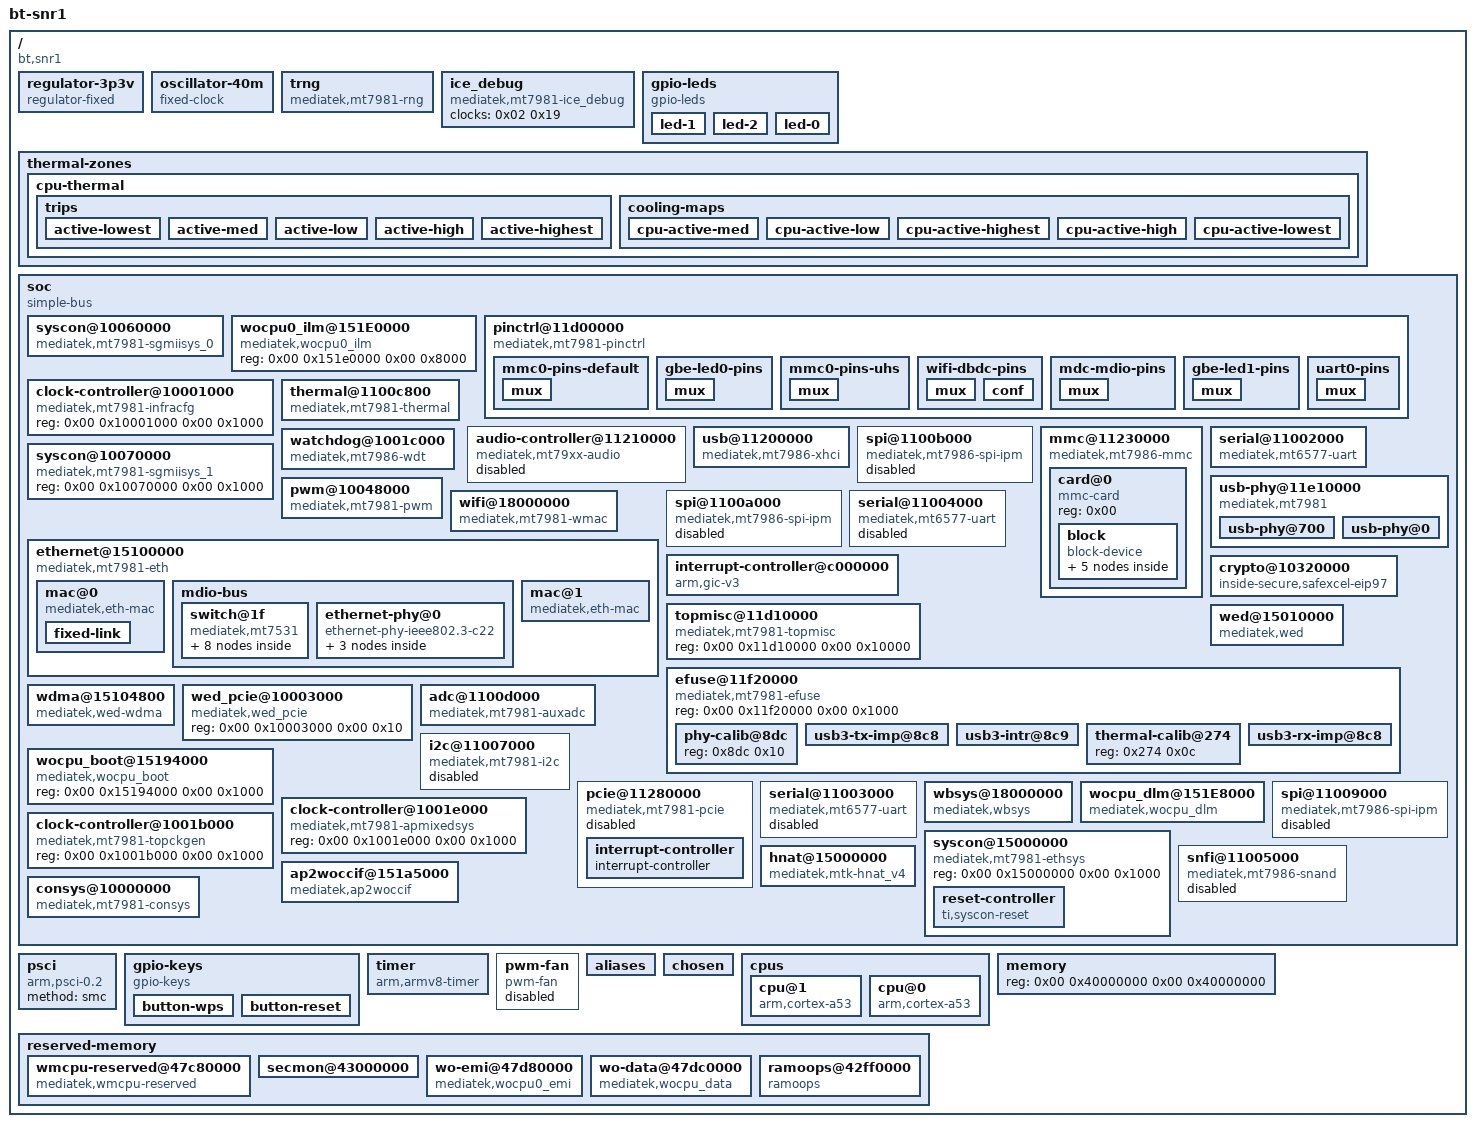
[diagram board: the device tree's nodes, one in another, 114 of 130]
/dts-v1/;

/ {
	#address-cells = <0x02>;
	model = "bt-snr1";
	#size-cells = <0x02>;
	interrupt-parent = <0x01>;
	compatible = "bt,snr1", "mediatek,mt7981";

	regulator-3p3v {
		regulator-max-microvolt = <0x325aa0>;
		regulator-boot-on;
		regulator-always-on;
		regulator-min-microvolt = <0x325aa0>;
		regulator-name = "fixed-3.3V";
		compatible = "regulator-fixed";
		phandle = <0x0c>;
	};

	oscillator-40m {
		clock-output-names = "clkxtal";
		#clock-cells = <0x00>;
		clock-frequency = <0x2625a00>;
		compatible = "fixed-clock";
		phandle = <0x22>;
	};

	trng {
		compatible = "mediatek,mt7981-rng";
	};

	ice_debug {
		clock-names = "ice_dbg";
		clocks = <0x02 0x19>;
		compatible = "mediatek,mt7981-ice_debug", "mediatek,mt2701-ice_debug";
		phandle = <0x21>;
	};

	gpio-leds {
		compatible = "gpio-leds";

		led-1 {
			label = "green:status";
			phandle = <0x52>;
			gpios = <0x10 0x0b 0x00>;
		};

		led-2 {
			label = "yellow:status";
			phandle = <0x53>;
			gpios = <0x10 0x0c 0x00>;
		};

		led-0 {
			label = "red:status";
			phandle = <0x51>;
			gpios = <0x10 0x0d 0x00>;
		};
	};

	thermal-zones {

		cpu-thermal {
			polling-delay = <0x3e8>;
			polling-delay-passive = <0x3e8>;
			thermal-sensors = <0x1a 0x00>;
			phandle = <0x4f>;

			trips {

				active-lowest {
					temperature = <0x9c40>;
					hysteresis = <0x7d0>;
					type = "active";
					phandle = <0x20>;
				};

				active-med {
					temperature = <0xc350>;
					hysteresis = <0x7d0>;
					type = "active";
					phandle = <0x1e>;
				};

				active-low {
					temperature = <0xafc8>;
					hysteresis = <0x7d0>;
					type = "active";
					phandle = <0x1f>;
				};

				active-high {
					temperature = <0xea60>;
					hysteresis = <0x7d0>;
					type = "active";
					phandle = <0x1d>;
				};

				active-highest {
					temperature = <0x11170>;
					hysteresis = <0x7d0>;
					type = "active";
					phandle = <0x1c>;
				};
			};

			cooling-maps {

				cpu-active-med {
					trip = <0x1e>;
					cooling-device = <0x1b 0x03 0x03>;
				};

				cpu-active-low {
					trip = <0x1f>;
					cooling-device = <0x1b 0x02 0x02>;
				};

				cpu-active-highest {
					trip = <0x1c>;
					cooling-device = <0x1b 0x07 0x07>;
				};

				cpu-active-high {
					trip = <0x1d>;
					cooling-device = <0x1b 0x05 0x05>;
				};

				cpu-active-lowest {
					trip = <0x20>;
					cooling-device = <0x1b 0x01 0x01>;
				};
			};
		};
	};

	soc {
		#address-cells = <0x02>;
		#size-cells = <0x02>;
		compatible = "simple-bus";
		ranges;

		syscon@10060000 {
			mediatek,pnswap;
			#clock-cells = <0x01>;
			compatible = "mediatek,mt7981-sgmiisys_0", "syscon";
			reg = <0x00 0x10060000 0x00 0x1000>;
			phandle = <0x12>;
		};

		wocpu0_ilm@151E0000 {
			compatible = "mediatek,wocpu0_ilm";
			reg = <0x00 0x151e0000 0x00 0x8000>;
			phandle = <0x4a>;
		};

		pinctrl@11d00000 {
			reg-names = "gpio", "iocfg_rt", "iocfg_rm", "iocfg_rb", "iocfg_lb", "iocfg_bl", "iocfg_tm", "iocfg_tl", "eint";
			gpio-controller;
			interrupts = <0x00 0xe1 0x04>;
			interrupt-parent = <0x01>;
			compatible = "mediatek,mt7981-pinctrl";
			#interrupt-cells = <0x02>;
			reg = <0x00 0x11d00000 0x00 0x1000 0x00 0x11c00000 0x00 0x1000 0x00 0x11c10000 0x00 0x1000 0x00 0x11d20000 0x00 0x1000 0x00 0x11e00000 0x00 0x1000 0x00 0x11e20000 0x00 0x1000 0x00 0x11f00000 0x00 0x1000 0x00 0x11f10000 0x00 0x1000 0x00 0x1000b000 0x00 0x1000>;
			phandle = <0x10>;
			#gpio-cells = <0x02>;
			gpio-ranges = <0x10 0x00 0x00 0x38>;
			interrupt-controller;

			mmc0-pins-default {
				phandle = <0x0d>;

				mux {
					function = "flash";
					groups = "emmc_45";
				};
			};

			gbe-led0-pins {
				phandle = <0x3b>;

				mux {
					function = "led";
					groups = "gbe_led0";
				};
			};

			mmc0-pins-uhs {
				phandle = <0x0e>;

				mux {
					function = "flash";
					groups = "emmc_45";
				};
			};

			wifi-dbdc-pins {
				phandle = <0x3a>;

				mux {
					function = "eth";
					groups = "wf0_mode1";
				};

				conf {
					pins = "WF_HB1", "WF_HB2", "WF_HB3", "WF_HB4", "WF_HB0", "WF_HB0_B", "WF_HB5", "WF_HB6", "WF_HB7", "WF_HB8", "WF_HB9", "WF_HB10", "WF_TOP_CLK", "WF_TOP_DATA", "WF_XO_REQ", "WF_CBA_RESETB", "WF_DIG_RESETB";
					drive-strength = <0x04>;
				};
			};

			mdc-mdio-pins {
				phandle = <0x39>;

				mux {
					function = "eth";
					groups = "smi_mdc_mdio";
				};
			};

			gbe-led1-pins {
				phandle = <0x3c>;

				mux {
					function = "led";
					groups = "gbe_led1";
				};
			};

			uart0-pins {
				phandle = <0x06>;

				mux {
					function = "uart";
					groups = "uart0";
				};
			};
		};

		clock-controller@10001000 {
			#clock-cells = <0x01>;
			compatible = "mediatek,mt7981-infracfg", "syscon";
			reg = <0x00 0x10001000 0x00 0x1000>;
			phandle = <0x02>;
		};

		thermal@1100c800 {
			nvmem-cells = <0x07>;
			clock-names = "therm", "auxadc";
			interrupts = <0x00 0x8a 0x04>;
			clocks = <0x02 0x1d 0x02 0x30>;
			mediatek,apmixedsys = <0x09>;
			#thermal-sensor-cells = <0x01>;
			compatible = "mediatek,mt7981-thermal", "mediatek,mt7986-thermal";
			nvmem-cell-names = "calibration-data";
			reg = <0x00 0x1100c800 0x00 0x800>;
			phandle = <0x1a>;
			mediatek,auxadc = <0x08>;
		};

		audio-controller@11210000 {
			clock-names = "aud_bus_ck", "aud_26m_ck", "aud_l_ck", "aud_aud_ck", "aud_eg2_ck", "aud_sel";
			assigned-clocks = <0x03 0x65 0x03 0x66 0x03 0x67 0x03 0x68>;
			assigned-clock-parents = <0x03 0x10 0x03 0x12 0x03 0x10 0x03 0x12>;
			interrupts = <0x00 0x6a 0x04>;
			clocks = <0x02 0x13 0x02 0x14 0x02 0x15 0x02 0x16 0x02 0x17 0x03 0x65>;
			compatible = "mediatek,mt79xx-audio";
			status = "disabled";
			reg = <0x00 0x11210000 0x00 0x9000>;
			phandle = <0x35>;
		};

		usb@11200000 {
			clock-names = "sys_ck", "ref_ck", "mcu_ck", "dma_ck", "xhci_ck";
			reg-names = "mac", "ippc";
			vusb33-supply = <0x0c>;
			interrupts = <0x00 0xad 0x04>;
			clocks = <0x02 0x37 0x02 0x38 0x02 0x35 0x02 0x36 0x03 0x6b>;
			compatible = "mediatek,mt7986-xhci", "mediatek,mtk-xhci";
			status = "okay";
			phys = <0x0a 0x03 0x0b 0x04>;
			reg = <0x00 0x11200000 0x00 0x2e00 0x00 0x11203e00 0x00 0x100>;
			phandle = <0x34>;
		};

		spi@1100b000 {
			#address-cells = <0x01>;
			clock-names = "parent-clk", "sel-clk", "spi-clk", "hclk";
			interrupts = <0x00 0x8d 0x04>;
			clocks = <0x03 0x02 0x03 0x4f 0x02 0x28 0x02 0x2a>;
			#size-cells = <0x00>;
			compatible = "mediatek,mt7986-spi-ipm", "mediatek,spi-ipm";
			status = "disabled";
			reg = <0x00 0x1100b000 0x00 0x100>;
			phandle = <0x33>;
		};

		mmc@11230000 {
			pinctrl-names = "default", "state_uhs";
			pinctrl-0 = <0x0d>;
			clock-names = "source", "hclk", "axi_cg", "ahb_cg";
			assigned-clocks = <0x03 0x54 0x03 0x55>;
			assigned-clock-parents = <0x03 0x02 0x03 0x1c>;
			bus-width = <0x08>;
			non-removable;
			interrupts = <0x00 0x8f 0x04>;
			clocks = <0x02 0x2c 0x02 0x2d 0x02 0x2f 0x02 0x2e>;
			vmmc-supply = <0x0c>;
			compatible = "mediatek,mt7986-mmc", "mediatek,mt7981-mmc";
			pinctrl-1 = <0x0e>;
			status = "okay";
			reg = <0x00 0x11230000 0x00 0x1000 0x00 0x11c20000 0x00 0x1000>;
			phandle = <0x36>;
			max-frequency = <0x5f5e100>;
			cap-mmc-highspeed;

			card@0 {
				compatible = "mmc-card";
				reg = <0x00>;

				block {
					compatible = "block-device";

					partitions {

						block-partition-factory {
							partname = "factory";

							nvmem-layout {
								#address-cells = <0x01>;
								#size-cells = <0x01>;
								compatible = "fixed-layout";

								eeprom@0 {
									reg = <0x00 0x1000>;
									phandle = <0x37>;
								};

								macaddr@2a {
									#nvmem-cell-cells = <0x01>;
									compatible = "mac-base";
									reg = <0x2a 0x06>;
									phandle = <0x17>;
								};
							};
						};
					};
				};
			};
		};

		serial@11002000 {
			pinctrl-names = "default";
			pinctrl-0 = <0x06>;
			clock-names = "baud", "bus";
			assigned-clocks = <0x03 0x50 0x02 0x01>;
			assigned-clock-parents = <0x03 0x00 0x03 0x50>;
			interrupts = <0x00 0x7b 0x04>;
			clocks = <0x02 0x01 0x02 0x1f>;
			compatible = "mediatek,mt6577-uart";
			status = "okay";
			reg = <0x00 0x11002000 0x00 0x400>;
			phandle = <0x2c>;
		};

		syscon@10070000 {
			#clock-cells = <0x01>;
			compatible = "mediatek,mt7981-sgmiisys_1", "syscon";
			reg = <0x00 0x10070000 0x00 0x1000>;
			phandle = <0x13>;
		};

		usb-phy@11e10000 {
			#address-cells = <0x01>;
			#size-cells = <0x01>;
			compatible = "mediatek,mt7981", "mediatek,generic-tphy-v2";
			ranges = <0x00 0x00 0x11e10000 0x1700>;
			status = "okay";
			phandle = <0x3d>;

			usb-phy@700 {
				clock-names = "ref";
				clocks = <0x03 0x64>;
				#phy-cells = <0x01>;
				status = "okay";
				reg = <0x700 0x900>;
				mediatek,syscon-type = <0x11 0x218 0x00>;
				phandle = <0x0b>;
			};

			usb-phy@0 {
				clock-names = "ref";
				clocks = <0x03 0x6c>;
				#phy-cells = <0x01>;
				reg = <0x00 0x700>;
				phandle = <0x0a>;
			};
		};

		watchdog@1001c000 {
			#reset-cells = <0x01>;
			interrupts = <0x00 0x6e 0x04>;
			compatible = "mediatek,mt7986-wdt", "mediatek,mt6589-wdt";
			status = "okay";
			reg = <0x00 0x1001c000 0x00 0x1000>;
			phandle = <0x28>;
		};

		pwm@10048000 {
			clock-names = "top", "main", "pwm1", "pwm2", "pwm3";
			clocks = <0x02 0x0e 0x02 0x0d 0x02 0x0f 0x02 0x10 0x02 0x11>;
			#pwm-cells = <0x02>;
			compatible = "mediatek,mt7981-pwm";
			reg = <0x00 0x10048000 0x00 0x1000>;
			phandle = <0x29>;
		};

		wifi@18000000 {
			compatible = "mediatek,mt7981-wmac";
			phandle = <0x4d>;
		};

		ethernet@15100000 {
			#reset-cells = <0x01>;
			#address-cells = <0x01>;
			clock-names = "fe", "gp2", "gp1", "wocpu0", "sgmii_tx250m", "sgmii_rx250m", "sgmii_cdr_ref", "sgmii_cdr_fb", "sgmii2_tx250m", "sgmii2_rx250m", "sgmii2_cdr_ref", "sgmii2_cdr_fb", "sgmii_ck", "netsys0", "netsys1";
			assigned-clocks = <0x03 0x60 0x03 0x61>;
			assigned-clock-parents = <0x03 0x1b 0x03 0x22>;
			interrupts = <0x00 0xbd 0x04 0x00 0xbe 0x04 0x00 0xbf 0x04 0x00 0xc0 0x04 0x00 0xc4 0x04 0x00 0xc5 0x04 0x00 0xc6 0x04 0x00 0xc7 0x04>;
			clocks = <0x05 0x00 0x05 0x01 0x05 0x02 0x05 0x03 0x12 0x00 0x12 0x01 0x12 0x02 0x12 0x03 0x13 0x00 0x13 0x01 0x13 0x02 0x13 0x03 0x03 0x40 0x03 0x5d 0x03 0x5e>;
			mediatek,sgmiisys = <0x12 0x13>;
			#size-cells = <0x00>;
			mediatek,ethsys = <0x05>;
			compatible = "mediatek,mt7981-eth";
			mediatek,wed = <0x14>;
			status = "okay";
			reg = <0x00 0x15100000 0x00 0x80000>;
			phandle = <0x43>;
			mediatek,infracfg = <0x11>;

			mac@0 {
				phy-mode = "2500base-x";
				nvmem-cells = <0x17 0x00>;
				mac-address = [a4 d8 ca 14 d4 20];
				compatible = "mediatek,eth-mac";
				nvmem-cell-names = "mac-address";
				reg = <0x00>;
				phandle = <0x16>;

				fixed-link {
					full-duplex;
					speed = <0x9c4>;
					pause;
				};
			};

			mdio-bus {
				#address-cells = <0x01>;
				#size-cells = <0x00>;
				phandle = <0x44>;

				switch@1f {
					reset-gpios = <0x10 0x27 0x00>;
					compatible = "mediatek,mt7531";
					reg = <0x1f>;
					phandle = <0x47>;

					ports {
						#address-cells = <0x01>;
						#size-cells = <0x00>;

						port@0 {
							label = "wan";
							reg = <0x00>;
						};

						port@3 {
							label = "lan3";
							reg = <0x03>;
						};

						port@1 {
							label = "lan1";
							reg = <0x01>;
						};

						port@6 {
							phy-mode = "2500base-x";
							reg = <0x06>;
							ethernet = <0x16>;

							fixed-link {
								full-duplex;
								speed = <0x9c4>;
								pause;
							};
						};

						port@4 {
							label = "lan4";
							reg = <0x04>;
						};

						port@2 {
							label = "lan2";
							reg = <0x02>;
						};
					};
				};

				ethernet-phy@0 {
					phy-mode = "gmii";
					nvmem-cells = <0x15>;
					compatible = "ethernet-phy-ieee802.3-c22";
					phy-is-integrated;
					nvmem-cell-names = "phy-cal-data";
					reg = <0x00>;
					phandle = <0x18>;

					leds {
						#address-cells = <0x01>;
						#size-cells = <0x00>;

						int-gbe-phy-led0@0 {
							function = "lan";
							status = "disabled";
							reg = <0x00>;
							phandle = <0x45>;
						};

						int-gbe-phy-led1@1 {
							function = "lan";
							status = "disabled";
							reg = <0x01>;
							phandle = <0x46>;
						};
					};
				};
			};

			mac@1 {
				phy-mode = "gmii";
				compatible = "mediatek,eth-mac";
				reg = <0x01>;
				phandle = <0x48>;
				phy-handle = <0x18>;
			};
		};

		spi@1100a000 {
			#address-cells = <0x01>;
			clock-names = "parent-clk", "sel-clk", "spi-clk", "hclk";
			interrupts = <0x00 0x8c 0x04>;
			clocks = <0x03 0x02 0x03 0x4e 0x02 0x27 0x02 0x29>;
			#size-cells = <0x00>;
			compatible = "mediatek,mt7986-spi-ipm", "mediatek,spi-ipm";
			status = "disabled";
			reg = <0x00 0x1100a000 0x00 0x100>;
			phandle = <0x32>;
		};

		serial@11004000 {
			clock-names = "baud", "bus";
			assigned-clocks = <0x03 0x50 0x02 0x03>;
			assigned-clock-parents = <0x03 0x00 0x03 0x50>;
			interrupts = <0x00 0x7d 0x04>;
			clocks = <0x02 0x03 0x02 0x21>;
			compatible = "mediatek,mt6577-uart";
			status = "disabled";
			reg = <0x00 0x11004000 0x00 0x400>;
			phandle = <0x2e>;
		};

		interrupt-controller@c000000 {
			interrupts = <0x01 0x09 0x04>;
			interrupt-parent = <0x01>;
			compatible = "arm,gic-v3";
			#interrupt-cells = <0x03>;
			reg = <0x00 0xc000000 0x00 0x40000 0x00 0xc080000 0x00 0x200000>;
			phandle = <0x01>;
			interrupt-controller;
		};

		topmisc@11d10000 {
			#clock-cells = <0x01>;
			compatible = "mediatek,mt7981-topmisc", "syscon";
			reg = <0x00 0x11d10000 0x00 0x10000>;
			phandle = <0x11>;
		};

		crypto@10320000 {
			clock-names = "top_eip97_ck";
			assigned-clocks = <0x03 0x63>;
			assigned-clock-parents = <0x03 0x15>;
			interrupts = <0x00 0x74 0x04 0x00 0x75 0x04 0x00 0x76 0x04 0x00 0x77 0x04>;
			clocks = <0x03 0x42>;
			compatible = "inside-secure,safexcel-eip97";
			interrupt-names = "ring0", "ring1", "ring2", "ring3";
			reg = <0x00 0x10320000 0x00 0x40000>;
			phandle = <0x2b>;
		};

		wed@15010000 {
			wed_num = <0x02>;
			interrupts = <0x00 0xcd 0x04 0x00 0xce 0x04>;
			interrupt-parent = <0x01>;
			pci_slot_map = <0x00 0x01>;
			compatible = "mediatek,wed";
			reg = <0x00 0x15010000 0x00 0x1000 0x00 0x15011000 0x00 0x1000>;
			phandle = <0x14>;
		};

		efuse@11f20000 {
			#address-cells = <0x01>;
			#size-cells = <0x01>;
			compatible = "mediatek,mt7981-efuse", "mediatek,efuse";
			status = "okay";
			reg = <0x00 0x11f20000 0x00 0x1000>;
			phandle = <0x3e>;

			phy-calib@8dc {
				reg = <0x8dc 0x10>;
				phandle = <0x15>;
			};

			usb3-tx-imp@8c8 {
				bits = <0x05 0x05>;
				reg = <0x8c8 0x02>;
				phandle = <0x40>;
			};

			usb3-intr@8c9 {
				bits = <0x02 0x06>;
				reg = <0x8c9 0x01>;
				phandle = <0x41>;
			};

			thermal-calib@274 {
				reg = <0x274 0x0c>;
				phandle = <0x07>;
			};

			usb3-rx-imp@8c8 {
				bits = <0x00 0x05>;
				reg = <0x8c8 0x01>;
				phandle = <0x3f>;
			};
		};

		wdma@15104800 {
			compatible = "mediatek,wed-wdma";
			reg = <0x00 0x15104800 0x00 0x400 0x00 0x15104c00 0x00 0x400>;
			phandle = <0x42>;
		};

		wed_pcie@10003000 {
			compatible = "mediatek,wed_pcie";
			reg = <0x00 0x10003000 0x00 0x10>;
			phandle = <0x27>;
		};

		adc@1100d000 {
			clock-names = "main", "32k";
			clocks = <0x02 0x30 0x02 0x31>;
			#io-channel-cells = <0x01>;
			compatible = "mediatek,mt7981-auxadc", "mediatek,mt7986-auxadc", "mediatek,mt7622-auxadc";
			reg = <0x00 0x1100d000 0x00 0x1000>;
			phandle = <0x08>;
		};

		wocpu_boot@15194000 {
			compatible = "mediatek,wocpu_boot";
			reg = <0x00 0x15194000 0x00 0x1000>;
			phandle = <0x4c>;
		};

		i2c@11007000 {
			clock-div = <0x01>;
			#address-cells = <0x01>;
			clock-names = "main", "dma", "arb", "pmic";
			interrupts = <0x00 0x88 0x04>;
			clocks = <0x02 0x1e 0x02 0x1a 0x02 0x33 0x02 0x34>;
			#size-cells = <0x00>;
			compatible = "mediatek,mt7981-i2c";
			status = "disabled";
			reg = <0x00 0x11007000 0x00 0x1000 0x00 0x10217080 0x00 0x80>;
			phandle = <0x30>;
		};

		pcie@11280000 {
			#address-cells = <0x03>;
			phy-names = "pcie-phy";
			bus-range = <0x00 0xff>;
			reg-names = "pcie-mac";
			interrupts = <0x00 0xa8 0x04>;
			clocks = <0x02 0x39 0x02 0x3a 0x02 0x3b 0x02 0x3c>;
			interrupt-map = <0x00 0x00 0x00 0x01 0x0f 0x00 0x00 0x00 0x00 0x02 0x0f 0x01 0x00 0x00 0x00 0x03 0x0f 0x02 0x00 0x00 0x00 0x04 0x0f 0x03>;
			#size-cells = <0x02>;
			device_type = "pci";
			interrupt-map-mask = <0x00 0x00 0x00 0x07>;
			compatible = "mediatek,mt7981-pcie", "mediatek,mt8192-pcie";
			ranges = <0x82000000 0x00 0x20000000 0x00 0x20000000 0x00 0x10000000>;
			#interrupt-cells = <0x01>;
			status = "disabled";
			phys = <0x0b 0x02>;
			reg = <0x00 0x11280000 0x00 0x4000>;
			phandle = <0x38>;

			interrupt-controller {
				#address-cells = <0x00>;
				#interrupt-cells = <0x01>;
				phandle = <0x0f>;
				interrupt-controller;
			};
		};

		serial@11003000 {
			clock-names = "baud", "bus";
			assigned-clocks = <0x03 0x50 0x02 0x02>;
			assigned-clock-parents = <0x03 0x00 0x03 0x50>;
			interrupts = <0x00 0x7c 0x04>;
			clocks = <0x02 0x02 0x02 0x20>;
			compatible = "mediatek,mt6577-uart";
			status = "disabled";
			reg = <0x00 0x11003000 0x00 0x400>;
			phandle = <0x2d>;
		};

		wbsys@18000000 {
			interrupts = <0x00 0xd5 0x04 0x00 0xd6 0x04 0x00 0xd7 0x04 0x00 0xd8 0x04>;
			compatible = "mediatek,wbsys";
			chip_id = <0x7981>;
			reg = <0x00 0x18000000 0x00 0x1000000>;
			phandle = <0x4e>;
		};

		wocpu_dlm@151E8000 {
			resets = <0x19 0x00>;
			compatible = "mediatek,wocpu_dlm";
			reg = <0x00 0x151e8000 0x00 0x2000 0x00 0x151f8000 0x00 0x2000>;
			phandle = <0x4b>;
			reset-names = "wocpu_rst";
		};

		clock-controller@1001e000 {
			#clock-cells = <0x01>;
			compatible = "mediatek,mt7981-apmixedsys", "syscon";
			reg = <0x00 0x1001e000 0x00 0x1000>;
			phandle = <0x09>;
		};

		clock-controller@1001b000 {
			#clock-cells = <0x01>;
			compatible = "mediatek,mt7981-topckgen", "syscon";
			reg = <0x00 0x1001b000 0x00 0x1000>;
			phandle = <0x03>;
		};

		syscon@15000000 {
			#reset-cells = <0x01>;
			#address-cells = <0x01>;
			#size-cells = <0x01>;
			#clock-cells = <0x01>;
			compatible = "mediatek,mt7981-ethsys", "syscon";
			reg = <0x00 0x15000000 0x00 0x1000>;
			phandle = <0x05>;

			reset-controller {
				#reset-cells = <0x01>;
				ti,reset-bits = <0x34 0x04 0x34 0x04 0x34 0x04 0x28>;
				compatible = "ti,syscon-reset";
				phandle = <0x19>;
			};
		};

		spi@11009000 {
			#address-cells = <0x01>;
			clock-names = "parent-clk", "sel-clk", "spi-clk", "hclk";
			interrupts = <0x00 0x8e 0x04>;
			clocks = <0x03 0x02 0x03 0x4e 0x02 0x22 0x02 0x23>;
			#size-cells = <0x00>;
			compatible = "mediatek,mt7986-spi-ipm", "mediatek,spi-ipm";
			status = "disabled";
			reg = <0x00 0x11009000 0x00 0x100>;
			phandle = <0x31>;
		};

		snfi@11005000 {
			#address-cells = <0x01>;
			clock-names = "pad_clk", "nfi_clk", "nfi_hclk";
			reg-names = "nfi", "ecc";
			assigned-clocks = <0x03 0x4d 0x03 0x4c>;
			assigned-clock-parents = <0x03 0x06 0x03 0x06>;
			interrupts = <0x00 0x79 0x04>;
			clocks = <0x02 0x25 0x02 0x24 0x02 0x26>;
			#size-cells = <0x00>;
			compatible = "mediatek,mt7986-snand";
			status = "disabled";
			reg = <0x00 0x11005000 0x00 0x1000 0x00 0x11006000 0x00 0x1000>;
			phandle = <0x2f>;
		};

		hnat@15000000 {
			resets = <0x05 0x00>;
			mtketh-wan = "eth1";
			mtketh-ppe-num = <0x02>;
			compatible = "mediatek,mtk-hnat_v4";
			ext-devices-prefix = "usb", "wwan", "rmnet", "eth2", "eth3", "eth4";
			reg = <0x00 0x15100000 0x00 0x80000>;
			phandle = <0x2a>;
			reset-names = "mtketh";
			mtketh-max-gmac = <0x02>;
			mtketh-lan = "eth0";
		};

		ap2woccif@151a5000 {
			interrupts = <0x00 0xd3 0x04 0x00 0xd4 0x04>;
			interrupt-parent = <0x01>;
			compatible = "mediatek,ap2woccif";
			reg = <0x00 0x151a5000 0x00 0x1000 0x00 0x151ad000 0x00 0x1000>;
			phandle = <0x49>;
		};

		consys@10000000 {
			clock-names = "mcu", "ap2conn";
			memory-region = <0x04>;
			clocks = <0x03 0x5f 0x03 0x5c>;
			compatible = "mediatek,mt7981-consys";
			reg = <0x00 0x10000000 0x00 0x8600000>;
			phandle = <0x26>;
		};
	};

	psci {
		method = "smc";
		compatible = "arm,psci-0.2";
	};

	gpio-keys {
		compatible = "gpio-keys";

		button-wps {
			label = "wps";
			linux,code = <0x211>;
			gpios = <0x10 0x00 0x01>;
		};

		button-reset {
			label = "reset";
			linux,code = <0x198>;
			gpios = <0x10 0x01 0x00>;
		};
	};

	timer {
		interrupts = <0x01 0x0d 0x08 0x01 0x0e 0x08 0x01 0x0b 0x08 0x01 0x0a 0x08>;
		interrupt-parent = <0x01>;
		clock-frequency = <0xc65d40>;
		compatible = "arm,armv8-timer";
	};

	pwm-fan {
		cooling-levels = <0x00 0x3f 0x5f 0x7f 0x9f 0xbf 0xdf 0xff>;
		compatible = "pwm-fan";
		status = "disabled";
		phandle = <0x1b>;
		#cooling-cells = <0x02>;
	};

	aliases {
		led-boot = "/gpio-leds/led-0";
		led-upgrade = "/gpio-leds/led-0";
		led-running = "/gpio-leds/led-1";
		led-failsafe = "/gpio-leds/led-0";
		serial0 = "/soc/serial@11002000";
	};

	chosen {
		u-boot,version = "2023.07";
		bootargs = "console=ttyS0,115200n1 loglevel=8 earlycon=uart8250,mmio32,0x11002000 root=PARTLABEL=rootfs rootwait rootfstype=squashfs,f2fs";
		u-boot,bootconf = "config-1";
		phandle = <0x50>;
		stdout-path = "serial0:115200n8";
	};

	cpus {
		#address-cells = <0x01>;
		#size-cells = <0x00>;

		cpu@1 {
			device_type = "cpu";
			compatible = "arm,cortex-a53";
			reg = <0x01>;
			enable-method = "psci";
		};

		cpu@0 {
			device_type = "cpu";
			compatible = "arm,cortex-a53";
			reg = <0x00>;
			enable-method = "psci";
		};
	};

	__symbols__ {
		wifi_dbdc_pins = "/soc/pinctrl@11d00000/wifi-dbdc-pins";
		pwm = "/soc/pwm@10048000";
		thermal = "/soc/thermal@1100c800";
		wocpu_dlm = "/soc/wocpu_dlm@151E8000";
		ethsysrst = "/soc/syscon@15000000/reset-controller";
		spi2 = "/soc/spi@11009000";
		u3port0 = "/soc/usb-phy@11e10000/usb-phy@700";
		wbsys = "/soc/wbsys@18000000";
		crypto = "/soc/crypto@10320000";
		secmon_reserved = "/reserved-memory/secmon@43000000";
		ap2woccif = "/soc/ap2woccif@151a5000";
		gmac0 = "/soc/ethernet@15100000/mac@0";
		int_gbe_phy = "/soc/ethernet@15100000/mdio-bus/ethernet-phy@0";
		reg_3p3v = "/regulator-3p3v";
		spi0 = "/soc/spi@1100a000";
		phy_calibration = "/soc/efuse@11f20000/phy-calib@8dc";
		afe = "/soc/audio-controller@11210000";
		wifi = "/soc/wifi@18000000";
		infracfg = "/soc/clock-controller@10001000";
		cpu_trip_active_med = "/thermal-zones/cpu-thermal/trips/active-med";
		apmixedsys = "/soc/clock-controller@1001e000";
		cpu_trip_active_low = "/thermal-zones/cpu-thermal/trips/active-low";
		u2port0 = "/soc/usb-phy@11e10000/usb-phy@0";
		xhci = "/soc/usb@11200000";
		cpu_trip_active_highest = "/thermal-zones/cpu-thermal/trips/active-highest";
		status_red_led = "/gpio-leds/led-0";
		int_gbe_phy_led1 = "/soc/ethernet@15100000/mdio-bus/ethernet-phy@0/leds/int-gbe-phy-led1@1";
		comb_rx_imp_p0 = "/soc/efuse@11f20000/usb3-rx-imp@8c8";
		cpu_thermal = "/thermal-zones/cpu-thermal";
		snand = "/soc/snfi@11005000";
		wo_emi0 = "/reserved-memory/wo-emi@47d80000";
		cpu_boot = "/soc/wocpu_boot@15194000";
		uart2 = "/soc/serial@11004000";
		eth = "/soc/ethernet@15100000";
		gic = "/soc/interrupt-controller@c000000";
		comb_tx_imp_p0 = "/soc/efuse@11f20000/usb3-tx-imp@8c8";
		switch = "/soc/ethernet@15100000/mdio-bus/switch@1f";
		uart0 = "/soc/serial@11002000";
		mdio_pins = "/soc/pinctrl@11d00000/mdc-mdio-pins";
		thermal_calibration = "/soc/efuse@11f20000/thermal-calib@274";
		mmc0_pins_uhs = "/soc/pinctrl@11d00000/mmc0-pins-uhs";
		consys = "/soc/consys@10000000";
		mdio_bus = "/soc/ethernet@15100000/mdio-bus";
		sgmiisys0 = "/soc/syscon@10060000";
		eeprom_factory_0 = "/soc/mmc@11230000/card@0/block/partitions/block-partition-factory/nvmem-layout/eeprom@0";
		pcie = "/soc/pcie@11280000";
		ethsys = "/soc/syscon@15000000";
		macaddr_factory_2a = "/soc/mmc@11230000/card@0/block/partitions/block-partition-factory/nvmem-layout/macaddr@2a";
		gbe_led1_pins = "/soc/pinctrl@11d00000/gbe-led1-pins";
		status_green_led = "/gpio-leds/led-1";
		hnat = "/soc/hnat@15000000";
		gmac1 = "/soc/ethernet@15100000/mac@1";
		spi1 = "/soc/spi@1100b000";
		i2c0 = "/soc/i2c@11007000";
		mmc0_pins_default = "/soc/pinctrl@11d00000/mmc0-pins-default";
		gbe_led0_pins = "/soc/pinctrl@11d00000/gbe-led0-pins";
		mmc0 = "/soc/mmc@11230000";
		led_yellow = "/gpio-leds/led-2";
		chosen = "/chosen";
		wo_data = "/reserved-memory/wo-data@47dc0000";
		int_gbe_phy_led0 = "/soc/ethernet@15100000/mdio-bus/ethernet-phy@0/leds/int-gbe-phy-led0@0";
		cpu_trip_active_lowest = "/thermal-zones/cpu-thermal/trips/active-lowest";
		wmcpu_emi = "/reserved-memory/wmcpu-reserved@47c80000";
		clk40m = "/oscillator-40m";
		topckgen = "/soc/clock-controller@1001b000";
		topmisc = "/soc/topmisc@11d10000";
		ice = "/ice_debug";
		auxadc = "/soc/adc@1100d000";
		pio = "/soc/pinctrl@11d00000";
		efuse = "/soc/efuse@11f20000";
		comb_intr_p0 = "/soc/efuse@11f20000/usb3-intr@8c9";
		fan = "/pwm-fan";
		wed = "/soc/wed@15010000";
		uart1 = "/soc/serial@11003000";
		wdma = "/soc/wdma@15104800";
		wocpu0_ilm = "/soc/wocpu0_ilm@151E0000";
		wed_pcie = "/soc/wed_pcie@10003000";
		sgmiisys1 = "/soc/syscon@10070000";
		usb_phy = "/soc/usb-phy@11e10000";
		pcie_intc = "/soc/pcie@11280000/interrupt-controller";
		watchdog = "/soc/watchdog@1001c000";
		uart0_pins = "/soc/pinctrl@11d00000/uart0-pins";
		cpu_trip_active_high = "/thermal-zones/cpu-thermal/trips/active-high";
	};

	reserved-memory {
		#address-cells = <0x02>;
		#size-cells = <0x02>;
		ranges;

		wmcpu-reserved@47c80000 {
			compatible = "mediatek,wmcpu-reserved";
			reg = <0x00 0x47c80000 0x00 0x100000>;
			phandle = <0x04>;
			no-map;
		};

		secmon@43000000 {
			reg = <0x00 0x43000000 0x00 0x30000>;
			phandle = <0x23>;
			no-map;
		};

		wo-emi@47d80000 {
			compatible = "mediatek,wocpu0_emi";
			reg = <0x00 0x47d80000 0x00 0x40000>;
			phandle = <0x24>;
			no-map;
			shared = <0x00>;
		};

		wo-data@47dc0000 {
			compatible = "mediatek,wocpu_data";
			reg = <0x00 0x47dc0000 0x00 0x240000>;
			phandle = <0x25>;
			no-map;
			shared = <0x01>;
		};

		ramoops@42ff0000 {
			record-size = <0x1000>;
			compatible = "ramoops";
			reg = <0x00 0x42ff0000 0x00 0x10000>;
		};
	};

	memory {
		device_type = "memory";
		reg = <0x00 0x40000000 0x00 0x40000000>;
	};
};
